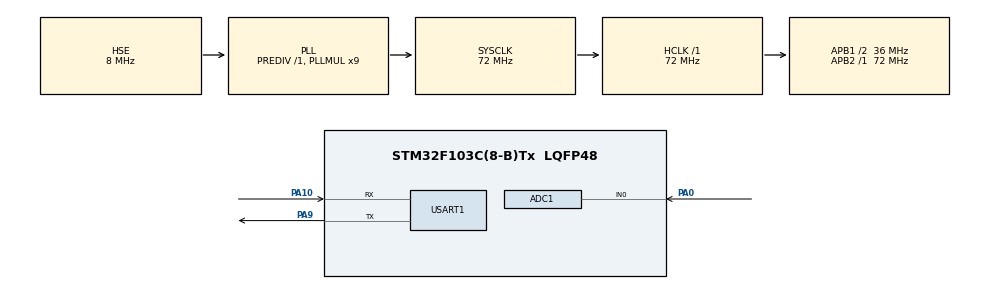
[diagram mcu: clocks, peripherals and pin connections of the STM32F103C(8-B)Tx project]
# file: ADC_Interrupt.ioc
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ADC1.Channel-0\#ChannelRegularConversion=ADC_CHANNEL_0
ADC1.ContinuousConvMode=ENABLE
ADC1.NbrOfConversionFlag=1
ADC1.Rank-0\#ChannelRegularConversion=1
ADC1.SamplingTime-0\#ChannelRegularConversion=ADC_SAMPLETIME_1CYCLE_5
ADC1.master=1
Mcu.Family=STM32F1
Mcu.Name=STM32F103C(8-B)Tx
Mcu.Package=LQFP48
NVIC.ADC1_2_IRQn=true\:0\:0\:false\:false\:true\:true\:true\:true
NVIC.PriorityGroup=NVIC_PRIORITYGROUP_4
PA0-WKUP.Signal=ADCx_IN0
PA10.Mode=Asynchronous
PA10.Signal=USART1_RX
PA13.Mode=Serial_Wire
PA13.Signal=SYS_JTMS-SWDIO
PA14.Mode=Serial_Wire
PA14.Signal=SYS_JTCK-SWCLK
PA9.Mode=Asynchronous
PA9.Signal=USART1_TX
PD0-OSC_IN.Mode=HSE-External-Oscillator
PD0-OSC_IN.Signal=RCC_OSC_IN
PD1-OSC_OUT.Mode=HSE-External-Oscillator
PD1-OSC_OUT.Signal=RCC_OSC_OUT
ProjectManager.HeapSize=0x200
ProjectManager.StackSize=0x400
ProjectManager.TargetToolchain=STM32CubeIDE
RCC.ADCPresc=RCC_ADCPCLK2_DIV6
RCC.AHBFreq_Value=72000000
RCC.APB1CLKDivider=RCC_HCLK_DIV2
RCC.APB1Freq_Value=36000000
RCC.APB1TimFreq_Value=72000000
RCC.APB2Freq_Value=72000000
RCC.APB2TimFreq_Value=72000000
RCC.HCLKFreq_Value=72000000
RCC.PLLMUL=RCC_PLL_MUL9
RCC.PLLSourceVirtual=RCC_PLLSOURCE_HSE
RCC.SYSCLKFreq_VALUE=72000000
RCC.SYSCLKSource=RCC_SYSCLKSOURCE_PLLCLK
RCC.USBFreq_Value=72000000
SH.ADCx_IN0.0=ADC1_IN0,IN0
USART1.VirtualMode=VM_ASYNC
board=custom

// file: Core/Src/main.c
/* USER CODE BEGIN Header */
/**
  ******************************************************************************
  * @file           : main.c
  * @brief          : Main program body
  ******************************************************************************
  * @attention
  *
  * Copyright (c) 2025 STMicroelectronics.
  * All rights reserved.
  *
  * This software is licensed under terms that can be found in the LICENSE file
  * in the root directory of this software component.
  * If no LICENSE file comes with this software, it is provided AS-IS.
  *
  ******************************************************************************
  */
/* USER CODE END Header */
#include "main.h"

/* USER CODE BEGIN Includes */

#include "stdio.h"   // Para sprintf()
#include "string.h"  // Para strlen()

/* USER CODE END Includes */

/* USER CODE BEGIN PD */

#define UART_TIMEOUT    100   // Timeout en ms para transmisión UART
#define BUFFER_SIZE     15    // Tamaño del buffer de transmisión

/* USER CODE END PD */

ADC_HandleTypeDef hadc1;

UART_HandleTypeDef huart1;

/* USER CODE BEGIN PV */

/**
 * @brief Variable para almacenar el valor digital del ADC
 * @note  Rango: 0-4095 (12 bits de resolución)
 *        Se actualiza automáticamente en el callback de interrupción
 */
uint32_t ADC_VAL;

/**
 * @brief Buffer para formatear la cadena a transmitir por UART
 * @note  Almacena el mensaje "ADC: XXXX\r\n" donde XXXX es el valor del ADC
 */
char buffer[BUFFER_SIZE];
/* USER CODE END PV */

void SystemClock_Config(void);
static void MX_GPIO_Init(void);
static void MX_ADC1_Init(void);
static void MX_USART1_UART_Init(void);

int main(void)
{

  /* MCU Configuration--------------------------------------------------------*/

  /* Reset of all peripherals, Initializes the Flash interface and the Systick. */
  HAL_Init();

  /* Configure the system clock */
  SystemClock_Config();

  /* Initialize all configured peripherals */
  MX_GPIO_Init();
  MX_ADC1_Init();
  MX_USART1_UART_Init();
  /* USER CODE BEGIN 2 */

  /**
   * ========== INICIALIZACIÓN DEL ADC EN MODO INTERRUPCIÓN ==========
   *
   * HAL_ADC_Start_IT():
   * - Inicia el ADC en modo interrupción
   * - Habilita la interrupción ADC1 en el NVIC
   * - El ADC comenzará conversiones continuas automáticamente
   * - Cada vez que finaliza una conversión, se genera una interrupción
   *   y se llama al callback HAL_ADC_ConvCpltCallback()
   */
  HAL_ADC_Start_IT(&hadc1);

  /* USER CODE END 2 */

  /* Infinite loop */
  /* USER CODE BEGIN WHILE */
  while (1)
  {

    /**
     * ========== BUCLE PRINCIPAL VACÍO ==========
     *
     * En el modo de interrupción, el bucle principal permanece vacío
     * porque todo el procesamiento se realiza en el callback.
     */

    /* USER CODE END WHILE */

  }
}

void SystemClock_Config(void)
{
  RCC_OscInitTypeDef RCC_OscInitStruct = {0};
  RCC_ClkInitTypeDef RCC_ClkInitStruct = {0};
  RCC_PeriphCLKInitTypeDef PeriphClkInit = {0};

  /** Initializes the RCC Oscillators according to the specified parameters
  * in the RCC_OscInitTypeDef structure.
  */
  RCC_OscInitStruct.OscillatorType = RCC_OSCILLATORTYPE_HSE;
  RCC_OscInitStruct.HSEState = RCC_HSE_ON;
  RCC_OscInitStruct.HSEPredivValue = RCC_HSE_PREDIV_DIV1;
  RCC_OscInitStruct.HSIState = RCC_HSI_ON;
  RCC_OscInitStruct.PLL.PLLState = RCC_PLL_ON;
  RCC_OscInitStruct.PLL.PLLSource = RCC_PLLSOURCE_HSE;
  RCC_OscInitStruct.PLL.PLLMUL = RCC_PLL_MUL9;
  if (HAL_RCC_OscConfig(&RCC_OscInitStruct) != HAL_OK)
  {
    Error_Handler();
  }

  /** Initializes the CPU, AHB and APB buses clocks
  */
  RCC_ClkInitStruct.ClockType = RCC_CLOCKTYPE_HCLK|RCC_CLOCKTYPE_SYSCLK
                              |RCC_CLOCKTYPE_PCLK1|RCC_CLOCKTYPE_PCLK2;
  RCC_ClkInitStruct.SYSCLKSource = RCC_SYSCLKSOURCE_PLLCLK;
  RCC_ClkInitStruct.AHBCLKDivider = RCC_SYSCLK_DIV1;
  RCC_ClkInitStruct.APB1CLKDivider = RCC_HCLK_DIV2;
  RCC_ClkInitStruct.APB2CLKDivider = RCC_HCLK_DIV1;

  if (HAL_RCC_ClockConfig(&RCC_ClkInitStruct, FLASH_LATENCY_2) != HAL_OK)
  {
    Error_Handler();
  }
  PeriphClkInit.PeriphClockSelection = RCC_PERIPHCLK_ADC;
  PeriphClkInit.AdcClockSelection = RCC_ADCPCLK2_DIV6;
  if (HAL_RCCEx_PeriphCLKConfig(&PeriphClkInit) != HAL_OK)
  {
    Error_Handler();
  }
}

static void MX_ADC1_Init(void)
{

  ADC_ChannelConfTypeDef sConfig = {0};

  /** Common config
  */
  hadc1.Instance = ADC1;
  hadc1.Init.ScanConvMode = ADC_SCAN_DISABLE;
  hadc1.Init.ContinuousConvMode = ENABLE;
  hadc1.Init.DiscontinuousConvMode = DISABLE;
  hadc1.Init.ExternalTrigConv = ADC_SOFTWARE_START;
  hadc1.Init.DataAlign = ADC_DATAALIGN_RIGHT;
  hadc1.Init.NbrOfConversion = 1;
  if (HAL_ADC_Init(&hadc1) != HAL_OK)
  {
    Error_Handler();
  }

  /** Configure Regular Channel
  */
  sConfig.Channel = ADC_CHANNEL_0;
  sConfig.Rank = ADC_REGULAR_RANK_1;
  sConfig.SamplingTime = ADC_SAMPLETIME_1CYCLE_5;
  if (HAL_ADC_ConfigChannel(&hadc1, &sConfig) != HAL_OK)
  {
    Error_Handler();
  }

}

static void MX_USART1_UART_Init(void)
{

  huart1.Instance = USART1;
  huart1.Init.BaudRate = 115200;
  huart1.Init.WordLength = UART_WORDLENGTH_8B;
  huart1.Init.StopBits = UART_STOPBITS_1;
  huart1.Init.Parity = UART_PARITY_NONE;
  huart1.Init.Mode = UART_MODE_TX_RX;
  huart1.Init.HwFlowCtl = UART_HWCONTROL_NONE;
  huart1.Init.OverSampling = UART_OVERSAMPLING_16;
  if (HAL_UART_Init(&huart1) != HAL_OK)
  {
    Error_Handler();
  }

}

static void MX_GPIO_Init(void)
{

  /* GPIO Ports Clock Enable */
  __HAL_RCC_GPIOD_CLK_ENABLE();
  __HAL_RCC_GPIOA_CLK_ENABLE();

}

/* USER CODE BEGIN 4 */

/**
  * @brief  Callback ejecutado cuando el DMA completa la conversión de todos los canales.
  * @param  hadc: puntero al manejador del ADC.
  * @retval None
  */
void HAL_ADC_ConvCpltCallback(ADC_HandleTypeDef *hadc)
{
  /* ========== PASO 1: Leer el valor convertido ========== */
  /**
   * HAL_ADC_GetValue():
   * - Lee el resultado de la conversión del registro de datos del ADC
   * - Retorna un valor de 12 bits (0-4095)
   * - La conversión ya está completa cuando se llama este callback
   * - No requiere espera adicional
   */
	ADC_VAL = HAL_ADC_GetValue(&hadc1);

   /* ========== PASO 2: Formatear el valor como texto ========== */
	sprintf(buffer, "ADC: %lu\r\n", ADC_VAL);

  /* ========== PASO 3: Transmitir el resultado por UART ========== */
	HAL_UART_Transmit(&huart1, (uint8_t*)buffer, strlen(buffer), 100);
}
/* USER CODE END 4 */

void Error_Handler(void)
{
  __disable_irq();
  while (1)
  {
  }
}
